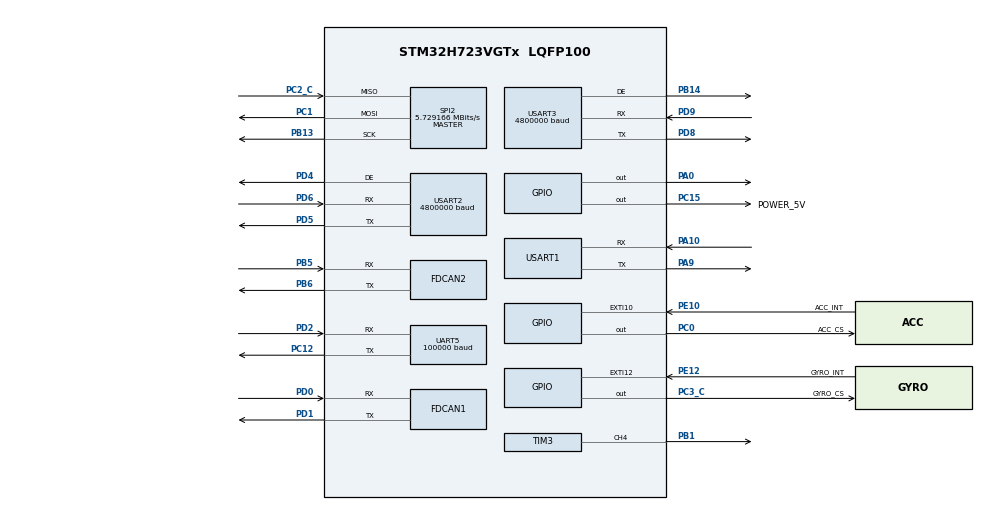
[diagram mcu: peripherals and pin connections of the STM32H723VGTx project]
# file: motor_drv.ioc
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CORTEX_M7.AccessPermission-Cortex_Memory_Protection_Unit_Region0_Settings=MPU_REGION_FULL_ACCESS
CORTEX_M7.BaseAddress-Cortex_Memory_Protection_Unit_Region0_Settings=0x24000000
CORTEX_M7.CPU_DCache=Enabled
CORTEX_M7.CPU_ICache=Enabled
CORTEX_M7.Enable-Cortex_Memory_Protection_Unit_Region0_Settings=MPU_REGION_ENABLE
CORTEX_M7.IsBufferable-Cortex_Memory_Protection_Unit_Region0_Settings=MPU_ACCESS_BUFFERABLE
CORTEX_M7.IsCacheable-Cortex_Memory_Protection_Unit_Region0_Settings=MPU_ACCESS_CACHEABLE
CORTEX_M7.MPU_Control=MPU_PRIVILEGED_DEFAULT
CORTEX_M7.Size-Cortex_Memory_Protection_Unit_Region0_Settings=MPU_REGION_SIZE_512KB
CORTEX_M7.TypeExtField-Cortex_Memory_Protection_Unit_Region0_Settings=MPU_TEX_LEVEL0
Dma.Request0=SPI2_RX
Dma.Request1=SPI2_TX
Dma.Request2=USART2_RX
Dma.Request3=USART2_TX
Dma.Request4=USART3_RX
Dma.Request5=USART3_TX
Dma.Request6=UART5_RX
Dma.Request7=USART1_TX
Dma.Request8=USART1_RX
Dma.SPI2_RX.0.Direction=DMA_PERIPH_TO_MEMORY
Dma.SPI2_RX.0.EventEnable=DISABLE
Dma.SPI2_RX.0.FIFOMode=DMA_FIFOMODE_DISABLE
Dma.SPI2_RX.0.Instance=DMA1_Stream0
Dma.SPI2_RX.0.MemDataAlignment=DMA_MDATAALIGN_BYTE
Dma.SPI2_RX.0.MemInc=DMA_MINC_ENABLE
Dma.SPI2_RX.0.Mode=DMA_NORMAL
Dma.SPI2_RX.0.PeriphDataAlignment=DMA_PDATAALIGN_BYTE
Dma.SPI2_RX.0.PeriphInc=DMA_PINC_DISABLE
Dma.SPI2_RX.0.Polarity=HAL_DMAMUX_REQ_GEN_RISING
Dma.SPI2_RX.0.Priority=DMA_PRIORITY_VERY_HIGH
Dma.SPI2_RX.0.RequestNumber=1
Dma.SPI2_RX.0.SignalID=NONE
Dma.SPI2_RX.0.SyncEnable=DISABLE
Dma.SPI2_RX.0.SyncPolarity=HAL_DMAMUX_SYNC_NO_EVENT
Dma.SPI2_RX.0.SyncRequestNumber=1
Dma.SPI2_RX.0.SyncSignalID=NONE
Dma.SPI2_TX.1.Direction=DMA_MEMORY_TO_PERIPH
Dma.SPI2_TX.1.EventEnable=DISABLE
Dma.SPI2_TX.1.FIFOMode=DMA_FIFOMODE_DISABLE
Dma.SPI2_TX.1.Instance=DMA1_Stream1
Dma.SPI2_TX.1.MemDataAlignment=DMA_MDATAALIGN_BYTE
Dma.SPI2_TX.1.MemInc=DMA_MINC_ENABLE
Dma.SPI2_TX.1.Mode=DMA_NORMAL
Dma.SPI2_TX.1.PeriphDataAlignment=DMA_PDATAALIGN_BYTE
Dma.SPI2_TX.1.PeriphInc=DMA_PINC_DISABLE
Dma.SPI2_TX.1.Polarity=HAL_DMAMUX_REQ_GEN_RISING
Dma.SPI2_TX.1.Priority=DMA_PRIORITY_HIGH
Dma.SPI2_TX.1.RequestNumber=1
Dma.SPI2_TX.1.SignalID=NONE
Dma.SPI2_TX.1.SyncEnable=DISABLE
Dma.SPI2_TX.1.SyncPolarity=HAL_DMAMUX_SYNC_NO_EVENT
Dma.SPI2_TX.1.SyncRequestNumber=1
Dma.SPI2_TX.1.SyncSignalID=NONE
Dma.UART5_RX.6.Direction=DMA_PERIPH_TO_MEMORY
Dma.UART5_RX.6.EventEnable=DISABLE
Dma.UART5_RX.6.FIFOMode=DMA_FIFOMODE_DISABLE
Dma.UART5_RX.6.Instance=DMA1_Stream6
Dma.UART5_RX.6.MemDataAlignment=DMA_MDATAALIGN_BYTE
Dma.UART5_RX.6.MemInc=DMA_MINC_ENABLE
Dma.UART5_RX.6.Mode=DMA_NORMAL
Dma.UART5_RX.6.PeriphDataAlignment=DMA_PDATAALIGN_BYTE
Dma.UART5_RX.6.PeriphInc=DMA_PINC_DISABLE
Dma.UART5_RX.6.Polarity=HAL_DMAMUX_REQ_GEN_RISING
Dma.UART5_RX.6.Priority=DMA_PRIORITY_HIGH
Dma.UART5_RX.6.RequestNumber=1
Dma.UART5_RX.6.SignalID=NONE
Dma.UART5_RX.6.SyncEnable=DISABLE
Dma.UART5_RX.6.SyncPolarity=HAL_DMAMUX_SYNC_NO_EVENT
Dma.UART5_RX.6.SyncRequestNumber=1
Dma.UART5_RX.6.SyncSignalID=NONE
Dma.USART1_RX.8.Direction=DMA_PERIPH_TO_MEMORY
Dma.USART1_RX.8.EventEnable=DISABLE
Dma.USART1_RX.8.FIFOMode=DMA_FIFOMODE_DISABLE
Dma.USART1_RX.8.Instance=DMA2_Stream0
Dma.USART1_RX.8.MemDataAlignment=DMA_MDATAALIGN_BYTE
Dma.USART1_RX.8.MemInc=DMA_MINC_ENABLE
Dma.USART1_RX.8.Mode=DMA_NORMAL
Dma.USART1_RX.8.PeriphDataAlignment=DMA_PDATAALIGN_BYTE
Dma.USART1_RX.8.PeriphInc=DMA_PINC_DISABLE
Dma.USART1_RX.8.Polarity=HAL_DMAMUX_REQ_GEN_RISING
Dma.USART1_RX.8.Priority=DMA_PRIORITY_LOW
Dma.USART1_RX.8.RequestNumber=1
Dma.USART1_RX.8.SignalID=NONE
Dma.USART1_RX.8.SyncEnable=DISABLE
Dma.USART1_RX.8.SyncPolarity=HAL_DMAMUX_SYNC_NO_EVENT
Dma.USART1_RX.8.SyncRequestNumber=1
Dma.USART1_RX.8.SyncSignalID=NONE
Dma.USART1_TX.7.Direction=DMA_MEMORY_TO_PERIPH
Dma.USART1_TX.7.EventEnable=DISABLE
Dma.USART1_TX.7.FIFOMode=DMA_FIFOMODE_DISABLE
Dma.USART1_TX.7.Instance=DMA1_Stream7
Dma.USART1_TX.7.MemDataAlignment=DMA_MDATAALIGN_BYTE
Dma.USART1_TX.7.MemInc=DMA_MINC_ENABLE
Dma.USART1_TX.7.Mode=DMA_NORMAL
Dma.USART1_TX.7.PeriphDataAlignment=DMA_PDATAALIGN_BYTE
Dma.USART1_TX.7.PeriphInc=DMA_PINC_DISABLE
Dma.USART1_TX.7.Polarity=HAL_DMAMUX_REQ_GEN_RISING
Dma.USART1_TX.7.Priority=DMA_PRIORITY_LOW
Dma.USART1_TX.7.RequestNumber=1
Dma.USART1_TX.7.SignalID=NONE
Dma.USART1_TX.7.SyncEnable=DISABLE
Dma.USART1_TX.7.SyncPolarity=HAL_DMAMUX_SYNC_NO_EVENT
Dma.USART1_TX.7.SyncRequestNumber=1
Dma.USART1_TX.7.SyncSignalID=NONE
Dma.USART2_RX.2.Direction=DMA_PERIPH_TO_MEMORY
Dma.USART2_RX.2.EventEnable=DISABLE
Dma.USART2_RX.2.FIFOMode=DMA_FIFOMODE_DISABLE
Dma.USART2_RX.2.Instance=DMA1_Stream2
Dma.USART2_RX.2.MemDataAlignment=DMA_MDATAALIGN_BYTE
Dma.USART2_RX.2.MemInc=DMA_MINC_ENABLE
Dma.USART2_RX.2.Mode=DMA_NORMAL
Dma.USART2_RX.2.PeriphDataAlignment=DMA_PDATAALIGN_BYTE
Dma.USART2_RX.2.PeriphInc=DMA_PINC_DISABLE
Dma.USART2_RX.2.Polarity=HAL_DMAMUX_REQ_GEN_RISING
Dma.USART2_RX.2.Priority=DMA_PRIORITY_LOW
Dma.USART2_RX.2.RequestNumber=1
Dma.USART2_RX.2.SignalID=NONE
Dma.USART2_RX.2.SyncEnable=DISABLE
Dma.USART2_RX.2.SyncPolarity=HAL_DMAMUX_SYNC_NO_EVENT
Dma.USART2_RX.2.SyncRequestNumber=1
Dma.USART2_RX.2.SyncSignalID=NONE
Dma.USART2_TX.3.Direction=DMA_MEMORY_TO_PERIPH
Dma.USART2_TX.3.EventEnable=DISABLE
Dma.USART2_TX.3.FIFOMode=DMA_FIFOMODE_DISABLE
Dma.USART2_TX.3.Instance=DMA1_Stream3
Dma.USART2_TX.3.MemDataAlignment=DMA_MDATAALIGN_BYTE
Dma.USART2_TX.3.MemInc=DMA_MINC_ENABLE
Dma.USART2_TX.3.Mode=DMA_NORMAL
Dma.USART2_TX.3.PeriphDataAlignment=DMA_PDATAALIGN_BYTE
Dma.USART2_TX.3.PeriphInc=DMA_PINC_DISABLE
Dma.USART2_TX.3.Polarity=HAL_DMAMUX_REQ_GEN_RISING
Dma.USART2_TX.3.Priority=DMA_PRIORITY_LOW
Dma.USART2_TX.3.RequestNumber=1
Dma.USART2_TX.3.SignalID=NONE
Dma.USART2_TX.3.SyncEnable=DISABLE
Dma.USART2_TX.3.SyncPolarity=HAL_DMAMUX_SYNC_NO_EVENT
Dma.USART2_TX.3.SyncRequestNumber=1
Dma.USART2_TX.3.SyncSignalID=NONE
Dma.USART3_RX.4.Direction=DMA_PERIPH_TO_MEMORY
Dma.USART3_RX.4.EventEnable=DISABLE
Dma.USART3_RX.4.FIFOMode=DMA_FIFOMODE_DISABLE
Dma.USART3_RX.4.Instance=DMA1_Stream4
Dma.USART3_RX.4.MemDataAlignment=DMA_MDATAALIGN_BYTE
Dma.USART3_RX.4.MemInc=DMA_MINC_ENABLE
Dma.USART3_RX.4.Mode=DMA_NORMAL
Dma.USART3_RX.4.PeriphDataAlignment=DMA_PDATAALIGN_BYTE
Dma.USART3_RX.4.PeriphInc=DMA_PINC_DISABLE
Dma.USART3_RX.4.Polarity=HAL_DMAMUX_REQ_GEN_RISING
Dma.USART3_RX.4.Priority=DMA_PRIORITY_LOW
Dma.USART3_RX.4.RequestNumber=1
Dma.USART3_RX.4.SignalID=NONE
Dma.USART3_RX.4.SyncEnable=DISABLE
Dma.USART3_RX.4.SyncPolarity=HAL_DMAMUX_SYNC_NO_EVENT
Dma.USART3_RX.4.SyncRequestNumber=1
Dma.USART3_RX.4.SyncSignalID=NONE
Dma.USART3_TX.5.Direction=DMA_MEMORY_TO_PERIPH
Dma.USART3_TX.5.EventEnable=DISABLE
Dma.USART3_TX.5.FIFOMode=DMA_FIFOMODE_DISABLE
Dma.USART3_TX.5.Instance=DMA1_Stream5
Dma.USART3_TX.5.MemDataAlignment=DMA_MDATAALIGN_BYTE
Dma.USART3_TX.5.MemInc=DMA_MINC_ENABLE
Dma.USART3_TX.5.Mode=DMA_NORMAL
Dma.USART3_TX.5.PeriphDataAlignment=DMA_PDATAALIGN_BYTE
Dma.USART3_TX.5.PeriphInc=DMA_PINC_DISABLE
Dma.USART3_TX.5.Polarity=HAL_DMAMUX_REQ_GEN_RISING
Dma.USART3_TX.5.Priority=DMA_PRIORITY_LOW
Dma.USART3_TX.5.RequestNumber=1
Dma.USART3_TX.5.SignalID=NONE
Dma.USART3_TX.5.SyncEnable=DISABLE
Dma.USART3_TX.5.SyncPolarity=HAL_DMAMUX_SYNC_NO_EVENT
Dma.USART3_TX.5.SyncRequestNumber=1
Dma.USART3_TX.5.SyncSignalID=NONE
FDCAN1.CalculateBaudRateNominal=1000000
FDCAN1.CalculateTimeBitNominal=1000
FDCAN1.CalculateTimeQuantumNominal=83.33333333333333
FDCAN1.NominalPrescaler=8
FDCAN1.NominalTimeSeg1=4
FDCAN1.NominalTimeSeg2=7
FDCAN1.RxFifo0ElmtsNbr=32
FDCAN1.TxFifoQueueElmtsNbr=16
FDCAN2.CalculateBaudRateNominal=1000000
FDCAN2.CalculateTimeBitNominal=1000
FDCAN2.CalculateTimeQuantumNominal=83.33333333333333
FDCAN2.NominalPrescaler=8
FDCAN2.NominalTimeSeg1=4
FDCAN2.NominalTimeSeg2=7
FDCAN2.RxFifo0ElmtsNbr=32
FREERTOS.BinarySemaphores01=imuBinarySem01,Static,imuBinarySemControlBlock
FREERTOS.INCLUDE_vTaskDelayUntil=1
FREERTOS.MEMORY_ALLOCATION=2
FREERTOS.Tasks01=defaultTask,0,128,StartDefaultTask,Default,NULL,Static,defaultTaskBuffer,defaultTaskControlBlock;MotorDrvThread,0,1024,MotorDrvTask,As weak,NULL,Dynamic,NULL,NULL
FREERTOS.configTOTAL_HEAP_SIZE=30720
Mcu.Family=STM32H7
Mcu.Name=STM32H723VGTx
Mcu.Package=LQFP100
NVIC.DMA1_Stream0_IRQn=true\:6\:0\:true\:false\:true\:true\:false\:true\:true
NVIC.DMA1_Stream1_IRQn=true\:6\:0\:true\:false\:true\:true\:false\:true\:true
NVIC.DMA1_Stream2_IRQn=true\:5\:0\:false\:false\:true\:true\:false\:true\:true
NVIC.DMA1_Stream3_IRQn=true\:5\:0\:false\:false\:true\:true\:false\:true\:true
NVIC.DMA1_Stream4_IRQn=true\:5\:0\:false\:false\:true\:true\:false\:true\:true
NVIC.DMA1_Stream5_IRQn=true\:5\:0\:false\:false\:true\:true\:false\:true\:true
NVIC.DMA1_Stream6_IRQn=true\:5\:0\:false\:false\:true\:true\:false\:true\:true
NVIC.DMA1_Stream7_IRQn=true\:5\:0\:false\:false\:true\:true\:false\:true\:true
NVIC.DMA2_Stream0_IRQn=true\:5\:0\:false\:false\:true\:true\:false\:true\:true
NVIC.EXTI15_10_IRQn=true\:6\:0\:true\:false\:true\:true\:true\:true\:true
NVIC.FDCAN1_IT0_IRQn=true\:5\:0\:false\:false\:true\:true\:true\:true\:true
NVIC.FDCAN1_IT1_IRQn=true\:5\:0\:false\:false\:true\:true\:true\:true\:true
NVIC.FDCAN2_IT0_IRQn=true\:5\:0\:false\:false\:true\:true\:true\:true\:true
NVIC.FDCAN2_IT1_IRQn=true\:5\:0\:false\:false\:true\:true\:true\:true\:true
NVIC.PriorityGroup=NVIC_PRIORITYGROUP_4
NVIC.SPI2_IRQn=true\:6\:0\:true\:false\:true\:true\:false\:true\:true
NVIC.TIM1_UP_IRQn=true\:15\:0\:false\:false\:true\:false\:false\:true\:true
NVIC.TimeBase=TIM1_UP_IRQn
NVIC.TimeBaseIP=TIM1
NVIC.UART5_IRQn=true\:5\:0\:false\:false\:true\:true\:true\:true\:true
NVIC.USART1_IRQn=true\:5\:0\:false\:false\:true\:true\:true\:true\:true
NVIC.USART2_IRQn=true\:5\:0\:false\:false\:true\:true\:true\:true\:true
NVIC.USART3_IRQn=true\:5\:0\:false\:false\:true\:true\:true\:true\:true
PA0.GPIO_Speed=GPIO_SPEED_FREQ_VERY_HIGH
PA0.Signal=GPIO_Output
PA10.Mode=Asynchronous
PA10.Signal=USART1_RX
PA13(JTMS/SWDIO).Mode=Serial_Wire
PA13(JTMS/SWDIO).Signal=DEBUG_JTMS-SWDIO
PA14(JTCK/SWCLK).Mode=Serial_Wire
PA14(JTCK/SWCLK).Signal=DEBUG_JTCK-SWCLK
PA9.Mode=Asynchronous
PA9.Signal=USART1_TX
PB1.Signal=S_TIM3_CH4
PB13.GPIO_Speed=GPIO_SPEED_FREQ_VERY_HIGH
PB13.Mode=Full_Duplex_Master
PB13.Signal=SPI2_SCK
PB14.GPIO_Speed=GPIO_SPEED_FREQ_VERY_HIGH
PB14.Mode=Hardware Flow Control (RS485)
PB14.Signal=USART3_DE
PB5.Mode=FDCAN_Activate
PB5.Signal=FDCAN2_RX
PB6.Mode=FDCAN_Activate
PB6.Signal=FDCAN2_TX
PC0.GPIO_Label=ACC_CS
PC0.GPIO_Speed=GPIO_SPEED_FREQ_VERY_HIGH
PC0.PinState=GPIO_PIN_SET
PC0.Signal=GPIO_Output
PC1.GPIO_Speed=GPIO_SPEED_FREQ_VERY_HIGH
PC1.Mode=Full_Duplex_Master
PC1.Signal=SPI2_MOSI
PC12.GPIO_Speed=GPIO_SPEED_FREQ_VERY_HIGH
PC12.Mode=Asynchronous
PC12.Signal=UART5_TX
PC15-OSC32_OUT.GPIO_Label=POWER_5V
PC15-OSC32_OUT.PinState=GPIO_PIN_SET
PC15-OSC32_OUT.Signal=GPIO_Output
PC2_C.GPIO_Speed=GPIO_SPEED_FREQ_VERY_HIGH
PC2_C.Mode=Full_Duplex_Master
PC2_C.Signal=SPI2_MISO
PC3_C.GPIO_Label=GYRO_CS
PC3_C.GPIO_Speed=GPIO_SPEED_FREQ_VERY_HIGH
PC3_C.PinState=GPIO_PIN_SET
PC3_C.Signal=GPIO_Output
PD0.Mode=FDCAN_Activate
PD0.Signal=FDCAN1_RX
PD1.Mode=FDCAN_Activate
PD1.Signal=FDCAN1_TX
PD2.GPIO_Speed=GPIO_SPEED_FREQ_VERY_HIGH
PD2.Mode=Asynchronous
PD2.Signal=UART5_RX
PD4.GPIO_Speed=GPIO_SPEED_FREQ_VERY_HIGH
PD4.Mode=Hardware Flow Control (RS485)
PD4.Signal=USART2_DE
PD5.GPIO_Speed=GPIO_SPEED_FREQ_VERY_HIGH
PD5.Mode=Asynchronous
PD5.Signal=USART2_TX
PD6.GPIO_Speed=GPIO_SPEED_FREQ_VERY_HIGH
PD6.Mode=Asynchronous
PD6.Signal=USART2_RX
PD8.GPIO_Speed=GPIO_SPEED_FREQ_VERY_HIGH
PD8.Mode=Asynchronous
PD8.Signal=USART3_TX
PD9.GPIO_Speed=GPIO_SPEED_FREQ_VERY_HIGH
PD9.Mode=Asynchronous
PD9.Signal=USART3_RX
PE10.GPIO_Label=ACC_INT
PE10.Signal=GPXTI10
PE12.GPIO_Label=GYRO_INT
PE12.Signal=GPXTI12
PH0-OSC_IN.Mode=HSE-External-Oscillator
PH0-OSC_IN.Signal=RCC_OSC_IN
PH1-OSC_OUT.Mode=HSE-External-Oscillator
PH1-OSC_OUT.Signal=RCC_OSC_OUT
ProjectManager.HeapSize=0x200
ProjectManager.StackSize=0x800
ProjectManager.TargetToolchain=MDK-ARM V5.27
RCC.ADCFreq_Value=96000000
RCC.APB1Freq_Value=137500000
RCC.APB2Freq_Value=137500000
RCC.APB3Freq_Value=137500000
RCC.APB4Freq_Value=137500000
RCC.CortexFreq_Value=550000000
RCC.D1PPRE=RCC_APB3_DIV2
RCC.D2PPRE1=RCC_APB1_DIV2
RCC.D2PPRE2=RCC_APB2_DIV2
RCC.D3PPRE=RCC_APB4_DIV2
RCC.DIVM1=3
RCC.DIVM2=2
RCC.DIVN1=68
RCC.DIVN2=16
RCC.DIVP1=1
RCC.DIVQ1=3
RCC.FDCANCLockSelection=RCC_FDCANCLKSOURCE_PLL2
RCC.HCLKFreq_Value=275000000
RCC.HPRE=RCC_HCLK_DIV2
RCC.HSE_VALUE=24000000
RCC.PLL2FRACN=0
RCC.PLL3FRACN=0
RCC.PLLFRACN=6144
RCC.PLLSourceVirtual=RCC_PLLSOURCE_HSE
RCC.SYSCLKFreq_VALUE=550000000
RCC.SYSCLKSource=RCC_SYSCLKSOURCE_PLLCLK
RCC.USBFreq_Value=183333333.33333334
SH.S_TIM3_CH4.0=TIM3_CH4,PWM Generation4 CH4
SPI2.BaudRatePrescaler=SPI_BAUDRATEPRESCALER_32
SPI2.CLKPhase=SPI_PHASE_2EDGE
SPI2.CLKPolarity=SPI_POLARITY_HIGH
SPI2.CalculateBaudRate=5.729166 MBits/s
SPI2.DataSize=SPI_DATASIZE_8BIT
SPI2.Direction=SPI_DIRECTION_2LINES
SPI2.Mode=SPI_MODE_MASTER
SPI2.VirtualType=VM_MASTER
TIM3.AutoReloadPreload=TIM_AUTORELOAD_PRELOAD_ENABLE
TIM3.Channel-PWM\ Generation4\ CH4=TIM_CHANNEL_4
TIM3.Period=10000-1
TIM3.Prescaler=24-1
UART5.BaudRate=100000
UART5.DMADisableonRxErrorParam=UART_ADVFEATURE_DMA_DISABLEONRXERROR
UART5.OverrunDisableParam=UART_ADVFEATURE_OVERRUN_DISABLE
UART5.Parity=PARITY_EVEN
UART5.WordLength=WORDLENGTH_9B
USART1.DMADisableonRxErrorParam=ADVFEATURE_DMA_DISABLEONRXERROR
USART1.OverrunDisableParam=ADVFEATURE_OVERRUN_DISABLE
USART1.VirtualMode-Asynchronous=VM_ASYNC
USART2.BaudRate=4800000
USART2.DMADisableonRxErrorParam=ADVFEATURE_DMA_DISABLEONRXERROR
USART2.OverSampling=UART_OVERSAMPLING_8
USART2.OverrunDisableParam=ADVFEATURE_OVERRUN_DISABLE
USART2.VirtualMode-Asynchronous=VM_ASYNC
USART2.VirtualMode-Hardware\ Flow\ Control\ (RS485)=VM_ASYNC
USART3.BaudRate=4800000
USART3.DMADisableonRxErrorParam=ADVFEATURE_DMA_DISABLEONRXERROR
USART3.OverSampling=UART_OVERSAMPLING_8
USART3.OverrunDisableParam=ADVFEATURE_OVERRUN_DISABLE
USART3.VirtualMode-Asynchronous=VM_ASYNC
USART3.VirtualMode-Hardware\ Flow\ Control\ (RS485)=VM_ASYNC
VP_FREERTOS_VS_CMSIS_V1.Mode=CMSIS_V1
VP_SYS_VS_tim1.Mode=TIM1
board=custom

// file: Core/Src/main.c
/* USER CODE BEGIN Header */
/**
 ******************************************************************************
 * @file           : main.c
 * @brief          : Main program body
 ******************************************************************************
 * @attention
 *
 * Copyright (c) 2024 STMicroelectronics.
 * All rights reserved.
 *
 * This software is licensed under terms that can be found in the LICENSE file
 * in the root directory of this software component.
 * If no LICENSE file comes with this software, it is provided AS-IS.
 *
 ******************************************************************************
 */
/* USER CODE END Header */
#include "main.h"
#include "cmsis_os.h"
#include "dma.h"
#include "fdcan.h"
#include "spi.h"
#include "tim.h"
#include "usart.h"
#include "gpio.h"

/* USER CODE BEGIN Includes */
#include "joint_motor.h"

/* USER CODE END Includes */

void SystemClock_Config(void);
void PeriphCommonClock_Config(void);
static void MPU_Config(void);
void MX_FREERTOS_Init(void);

int main(void)
{

  /* MPU Configuration--------------------------------------------------------*/
  MPU_Config();
  /* Enable the CPU Cache */

  /* Enable I-Cache---------------------------------------------------------*/
  SCB_EnableICache();

  /* Enable D-Cache---------------------------------------------------------*/
  SCB_EnableDCache();

  /* MCU Configuration--------------------------------------------------------*/

  /* Reset of all peripherals, Initializes the Flash interface and the Systick. */
  HAL_Init();

  /* Configure the system clock */
  SystemClock_Config();

  /* Configure the peripherals common clocks */
  PeriphCommonClock_Config();

  /* Initialize all configured peripherals */
  MX_GPIO_Init();
  MX_DMA_Init();
  MX_SPI2_Init();
  MX_TIM3_Init();
  MX_USART2_UART_Init();
  MX_USART3_UART_Init();
  MX_FDCAN1_Init();
  MX_UART5_Init();
  MX_USART1_UART_Init();
  MX_FDCAN2_Init();
  /* USER CODE BEGIN 2 */
  FDCAN_Config();

  __HAL_UART_ENABLE_IT(&huart2, UART_IT_IDLE);
  HAL_UART_Receive_DMA(&huart2, Usart2Type.RX_pData, RECEIVE_SIZE);
  __HAL_UART_ENABLE_IT(&huart3, UART_IT_IDLE);
  HAL_UART_Receive_DMA(&huart3, Usart3Type.RX_pData, RECEIVE_SIZE);

  joint_motor_set_mode(0);
  /* USER CODE END 2 */

  /* Call init function for freertos objects (in freertos.c) */
  MX_FREERTOS_Init();

  /* Start scheduler */
  osKernelStart();

  /* We should never get here as control is now taken by the scheduler */
  /* Infinite loop */
  while (1)
  {

  }
}

void SystemClock_Config(void)
{
  RCC_OscInitTypeDef RCC_OscInitStruct = {0};
  RCC_ClkInitTypeDef RCC_ClkInitStruct = {0};

  /** Supply configuration update enable
   */
  HAL_PWREx_ConfigSupply(PWR_LDO_SUPPLY);

  /** Configure the main internal regulator output voltage
   */
  __HAL_PWR_VOLTAGESCALING_CONFIG(PWR_REGULATOR_VOLTAGE_SCALE0);

  while (!__HAL_PWR_GET_FLAG(PWR_FLAG_VOSRDY))
  {
  }

  /** Initializes the RCC Oscillators according to the specified parameters
   * in the RCC_OscInitTypeDef structure.
   */
  RCC_OscInitStruct.OscillatorType = RCC_OSCILLATORTYPE_HSE;
  RCC_OscInitStruct.HSEState = RCC_HSE_ON;
  RCC_OscInitStruct.PLL.PLLState = RCC_PLL_ON;
  RCC_OscInitStruct.PLL.PLLSource = RCC_PLLSOURCE_HSE;
  RCC_OscInitStruct.PLL.PLLM = 3;
  RCC_OscInitStruct.PLL.PLLN = 68;
  RCC_OscInitStruct.PLL.PLLP = 1;
  RCC_OscInitStruct.PLL.PLLQ = 3;
  RCC_OscInitStruct.PLL.PLLR = 2;
  RCC_OscInitStruct.PLL.PLLRGE = RCC_PLL1VCIRANGE_3;
  RCC_OscInitStruct.PLL.PLLVCOSEL = RCC_PLL1VCOWIDE;
  RCC_OscInitStruct.PLL.PLLFRACN = 6144;
  if (HAL_RCC_OscConfig(&RCC_OscInitStruct) != HAL_OK)
  {
    Error_Handler();
  }

  /** Initializes the CPU, AHB and APB buses clocks
   */
  RCC_ClkInitStruct.ClockType = RCC_CLOCKTYPE_HCLK | RCC_CLOCKTYPE_SYSCLK | RCC_CLOCKTYPE_PCLK1 | RCC_CLOCKTYPE_PCLK2 | RCC_CLOCKTYPE_D3PCLK1 | RCC_CLOCKTYPE_D1PCLK1;
  RCC_ClkInitStruct.SYSCLKSource = RCC_SYSCLKSOURCE_PLLCLK;
  RCC_ClkInitStruct.SYSCLKDivider = RCC_SYSCLK_DIV1;
  RCC_ClkInitStruct.AHBCLKDivider = RCC_HCLK_DIV2;
  RCC_ClkInitStruct.APB3CLKDivider = RCC_APB3_DIV2;
  RCC_ClkInitStruct.APB1CLKDivider = RCC_APB1_DIV2;
  RCC_ClkInitStruct.APB2CLKDivider = RCC_APB2_DIV2;
  RCC_ClkInitStruct.APB4CLKDivider = RCC_APB4_DIV2;

  if (HAL_RCC_ClockConfig(&RCC_ClkInitStruct, FLASH_LATENCY_3) != HAL_OK)
  {
    Error_Handler();
  }
}

void PeriphCommonClock_Config(void)
{
  RCC_PeriphCLKInitTypeDef PeriphClkInitStruct = {0};

  /** Initializes the peripherals clock
   */
  PeriphClkInitStruct.PeriphClockSelection = RCC_PERIPHCLK_FDCAN;
  PeriphClkInitStruct.PLL2.PLL2M = 2;
  PeriphClkInitStruct.PLL2.PLL2N = 16;
  PeriphClkInitStruct.PLL2.PLL2P = 2;
  PeriphClkInitStruct.PLL2.PLL2Q = 2;
  PeriphClkInitStruct.PLL2.PLL2R = 2;
  PeriphClkInitStruct.PLL2.PLL2RGE = RCC_PLL2VCIRANGE_3;
  PeriphClkInitStruct.PLL2.PLL2VCOSEL = RCC_PLL2VCOWIDE;
  PeriphClkInitStruct.PLL2.PLL2FRACN = 0;
  PeriphClkInitStruct.FdcanClockSelection = RCC_FDCANCLKSOURCE_PLL2;
  if (HAL_RCCEx_PeriphCLKConfig(&PeriphClkInitStruct) != HAL_OK)
  {
    Error_Handler();
  }
}

/* MPU Configuration */

void MPU_Config(void)
{
  MPU_Region_InitTypeDef MPU_InitStruct = {0};

  /* Disables the MPU */
  HAL_MPU_Disable();

  /** Initializes and configures the Region and the memory to be protected
   */
  MPU_InitStruct.Enable = MPU_REGION_ENABLE;
  MPU_InitStruct.Number = MPU_REGION_NUMBER0;
  MPU_InitStruct.BaseAddress = 0x24000000;
  MPU_InitStruct.Size = MPU_REGION_SIZE_512KB;
  MPU_InitStruct.SubRegionDisable = 0x0;
  MPU_InitStruct.TypeExtField = MPU_TEX_LEVEL0;
  MPU_InitStruct.AccessPermission = MPU_REGION_FULL_ACCESS;
  MPU_InitStruct.DisableExec = MPU_INSTRUCTION_ACCESS_ENABLE;
  MPU_InitStruct.IsShareable = MPU_ACCESS_NOT_SHAREABLE;
  MPU_InitStruct.IsCacheable = MPU_ACCESS_CACHEABLE;
  MPU_InitStruct.IsBufferable = MPU_ACCESS_BUFFERABLE;

  HAL_MPU_ConfigRegion(&MPU_InitStruct);
  /* Enables the MPU */
  HAL_MPU_Enable(MPU_PRIVILEGED_DEFAULT);
}

void HAL_TIM_PeriodElapsedCallback(TIM_HandleTypeDef *htim)
{
  if (htim->Instance == TIM1)
  {
    HAL_IncTick();
  }
}

void Error_Handler(void)
{
  __disable_irq();
  while (1)
  {
  }
}

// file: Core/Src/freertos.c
/* USER CODE BEGIN Header */
/**
  ******************************************************************************
  * File Name          : freertos.c
  * Description        : Code for freertos applications
  ******************************************************************************
  * @attention
  *
  * Copyright (c) 2024 STMicroelectronics.
  * All rights reserved.
  *
  * This software is licensed under terms that can be found in the LICENSE file
  * in the root directory of this software component.
  * If no LICENSE file comes with this software, it is provided AS-IS.
  *
  ******************************************************************************
  */
/* USER CODE END Header */

#include "FreeRTOS.h"
#include "task.h"
#include "main.h"
#include "cmsis_os.h"

osThreadId defaultTaskHandle;
uint32_t defaultTaskBuffer[ 128 ];
osStaticThreadDef_t defaultTaskControlBlock;
osThreadId MotorDrvThreadHandle;
osSemaphoreId imuBinarySem01Handle;
osStaticSemaphoreDef_t imuBinarySemControlBlock;

void StartDefaultTask(void const * argument);
void MotorDrvTask(void const * argument);

void MX_FREERTOS_Init(void); /* (MISRA C 2004 rule 8.1) */

/* GetIdleTaskMemory prototype (linked to static allocation support) */
void vApplicationGetIdleTaskMemory( StaticTask_t **ppxIdleTaskTCBBuffer, StackType_t **ppxIdleTaskStackBuffer, uint32_t *pulIdleTaskStackSize );

/* USER CODE BEGIN GET_IDLE_TASK_MEMORY */
static StaticTask_t xIdleTaskTCBBuffer;
static StackType_t xIdleStack[configMINIMAL_STACK_SIZE];

void vApplicationGetIdleTaskMemory( StaticTask_t **ppxIdleTaskTCBBuffer, StackType_t **ppxIdleTaskStackBuffer, uint32_t *pulIdleTaskStackSize )
{
  *ppxIdleTaskTCBBuffer = &xIdleTaskTCBBuffer;
  *ppxIdleTaskStackBuffer = &xIdleStack[0];
  *pulIdleTaskStackSize = configMINIMAL_STACK_SIZE;
  /* place for user code */
}
/* USER CODE END GET_IDLE_TASK_MEMORY */

void MX_FREERTOS_Init(void) {

  /* Create the semaphores(s) */
  /* definition and creation of imuBinarySem01 */
  osSemaphoreStaticDef(imuBinarySem01, &imuBinarySemControlBlock);
  imuBinarySem01Handle = osSemaphoreCreate(osSemaphore(imuBinarySem01), 1);

  /* Create the thread(s) */
  /* definition and creation of defaultTask */
  osThreadStaticDef(defaultTask, StartDefaultTask, osPriorityNormal, 0, 128, defaultTaskBuffer, &defaultTaskControlBlock);
  defaultTaskHandle = osThreadCreate(osThread(defaultTask), NULL);

  /* definition and creation of MotorDrvThread */
  osThreadDef(MotorDrvThread, MotorDrvTask, osPriorityNormal, 0, 1024);
  MotorDrvThreadHandle = osThreadCreate(osThread(MotorDrvThread), NULL);

}

void StartDefaultTask(void const * argument)
{
  for(;;)
  {
    osDelay(1);
  }
}

__weak void MotorDrvTask(void const * argument)
{
  for(;;)
  {
    osDelay(1);
  }
}
